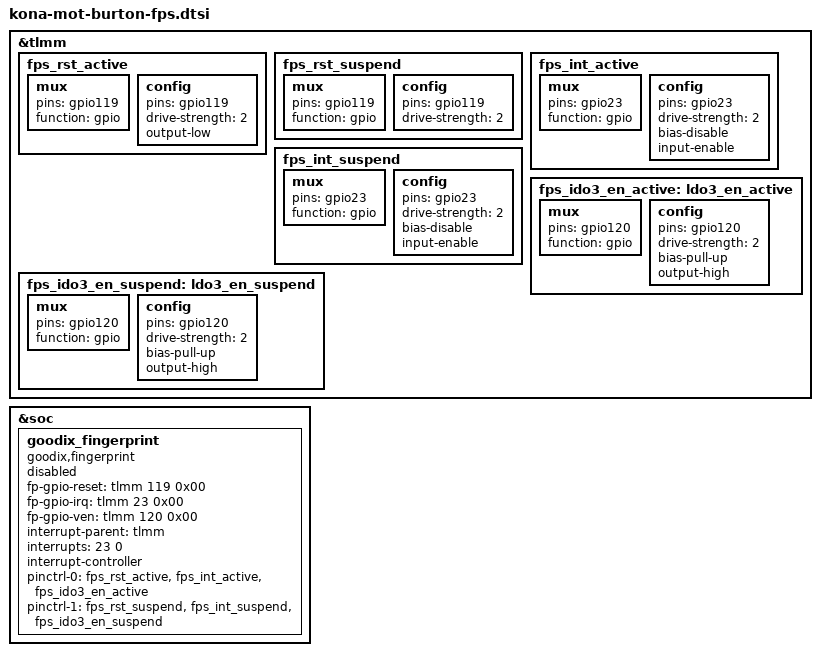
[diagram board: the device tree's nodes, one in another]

&tlmm {
	fps_rst_active: fps_rst_active {
		/* active state */
		mux {
			pins = "gpio119";
			function = "gpio";
		};

		config {
			pins = "gpio119";
			drive-strength = <2>; /* 2 MA */
			output-low;
		};
	};

	fps_rst_suspend: fps_rst_suspend {
		/* sleep state */
		mux {
			pins = "gpio119";
			function = "gpio";
		};

		config {
			pins = "gpio119";
			drive-strength = <2>; /* 2 MA */
		};
	};

	fps_int_active: fps_int_active {
		/* active state */
		mux {
			pins = "gpio23";
			function = "gpio";
		};

		config {
			pins = "gpio23";
			drive-strength = <2>; /* 2 MA */
			bias-disable;
			input-enable;
		};
	};

	fps_int_suspend: fps_int_suspend {
		/* sleep state */
		mux {
			pins = "gpio23";
			function = "gpio";
		};

		config {
			pins = "gpio23";
			drive-strength = <2>; /* 2 MA */
			bias-disable;
			input-enable;
		};
	};

	fps_ido3_en_active: ldo3_en_active {
		/* active state */
		mux {
			pins = "gpio120";
			function = "gpio";
		};

		config {
			pins = "gpio120";
			drive-strength = <2>; /* 2 MA */
			bias-pull-up;
			output-high;
		};
	};

	fps_ido3_en_suspend: ldo3_en_suspend {
		/* suspend state */
		mux {
			pins = "gpio120";
			function = "gpio";
		};

		config {
			pins = "gpio120";
			drive-strength = <2>; /* 2 MA */
			bias-pull-up;
			output-high;
		};
	};
};

&soc {
	goodix_fingerprint{
		status = "/chosen", "mmi,fps", "true";
		compatible = "goodix,fingerprint";
		fp-gpio-reset = <&tlmm 119 0x00>;
		fp-gpio-irq = <&tlmm 23  0x00>;
		fp-gpio-ven = <&tlmm 120 0x00>;
		interrupt-parent = <&tlmm>;
		interrupts = <23 0>;
		interrupt-controller;
		pinctrl-names = "default", "suspend";
		pinctrl-0 = <&fps_rst_active &fps_int_active &fps_ido3_en_active>;
		pinctrl-1 = <&fps_rst_suspend &fps_int_suspend &fps_ido3_en_suspend>;
	};
};
